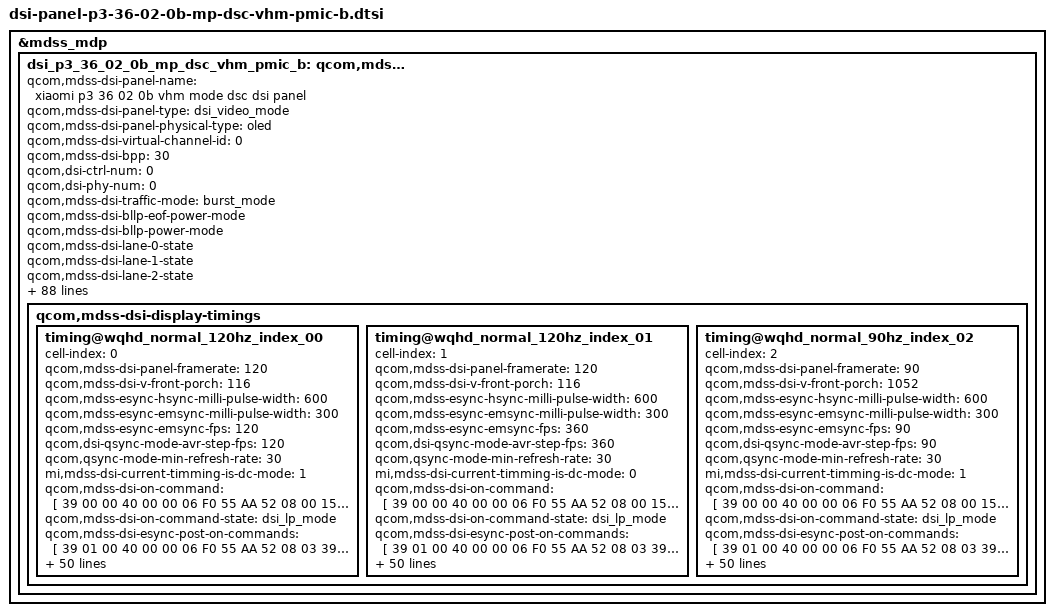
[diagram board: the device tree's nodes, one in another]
&mdss_mdp {
	dsi_p3_36_02_0b_mp_dsc_vhm_pmic_b: qcom,mdss_dsi_p3_36_02_0b_mp_dsc_vhm_pmic_b {
		qcom,mdss-dsi-panel-name = "xiaomi p3 36 02 0b vhm mode dsc dsi panel";
		qcom,mdss-dsi-panel-type = "dsi_video_mode";
		qcom,mdss-dsi-panel-physical-type = "oled";
		qcom,mdss-dsi-virtual-channel-id = <0>;
		qcom,mdss-dsi-bpp = <30>;
		qcom,dsi-ctrl-num = <0>;
		qcom,dsi-phy-num = <0>;
		qcom,mdss-dsi-traffic-mode = "burst_mode";
		qcom,mdss-dsi-bllp-eof-power-mode;
		qcom,mdss-dsi-bllp-power-mode;
		qcom,mdss-dsi-lane-0-state;
		qcom,mdss-dsi-lane-1-state;
		qcom,mdss-dsi-lane-2-state;
		qcom,mdss-dsi-lane-3-state;
		qcom,mdss-dsi-color-order = "rgb_swap_rgb";
		qcom,mdss-dsi-dma-trigger = "trigger_sw";
		qcom,mdss-dsi-mdp-trigger = "none";
		qcom,mdss-dsi-reset-sequence =<1 1>, <0 3>, <1 15>;
		qcom,mdss-pan-physical-width-dimension = <673>;
		qcom,mdss-pan-physical-height-dimension = <1466>;
		qcom,mdss-dsi-te-pin-select = <1>;
		qcom,mdss-dsi-wr-mem-start = <0x2c>;
		qcom,mdss-dsi-wr-mem-continue = <0x3c>;
		qcom,mdss-dsi-tx-eot-append;
		qcom,mdss-dsi-lp11-init;
		qcom,mdss-dsi-bl-inverted-dbv;
		qcom,bl-update-flag = "delay_until_first_frame";
		qcom,mdss-dsi-panel-hdr-enabled;
		qcom,mdss-dsi-panel-hdr-color-primaries = <14500 15500 32000
			17000 15500 30000 8000 3000>;
		qcom,mdss-dsi-panel-peak-brightness = <32000000>;
		qcom,mdss-dsi-panel-blackness-level = <3230>;
		//qcom,mdss-dsi-dma-schedule-line = <1>;
		//qcom,mdss-dsi-dma-schedule-window = <50>;
		qcom,spr-pack-type = "pentile";
		/*
		 * ###############################################################
		 * # Pentile SPR phases for SM8850 and later
		 * ###############################################################
		 * # RG/BG Type A    BG/RG Type A    GR/GB Type A    GB/GR Type A
		 * # R B R B ...     B R B R ...      R B R B ...     B R B R ...
		 * #  G G G G ...     G G G G ...    G G G G ...     G G G G ...
		 * #
		 * # RG/BG Type B    BG/RG Type B    GR/GB Type B    GB/GR Type B
		 * #  G G G G ...     G G G G ...    G G G G ...     G G G G ...
		 * # R B R B ...     B R B R ...      R B R B ...     B R B R ...
		 * ###############################################################
		 */
		qcom,spr-pentile-pack-type = "BG-RG Type A";
		xiaomi,mdss-panel-need-post-on-supply;
		xiaomi,mdss-dsi-gesture-reset-sequence = <0 10>, <1 5>, <0 3>, <1 15>;

		qcom,mdss-disable-cesta-hw-sleep;

		qcom,mdss-dsi-display-timings {
			timing@wqhd_normal_120hz_index_00 {
				#include "dsi-panel-p3-36-02-0b-mp-dsc-vhm-pmic-b-common.dtsi"
				cell-index = <0>;
				qcom,mdss-dsi-panel-framerate = <120>;

				qcom,mdss-dsi-v-front-porch = <116>;
				qcom,mdss-esync-hsync-milli-pulse-width = <600>;
				qcom,mdss-esync-emsync-milli-pulse-width = <300>;
				qcom,mdss-esync-emsync-fps = <120>;
				qcom,dsi-qsync-mode-avr-step-fps = <120>;
				qcom,qsync-mode-min-refresh-rate = <30>;

				mi,mdss-dsi-current-timming-is-dc-mode = <1>;

				qcom,mdss-dsi-on-command = [
					// dbv_vld_dly_em=2
					39 00 00 40 00 00 06 F0 55 AA 52 08 00
					15 00 00 40 00 00 02 6F 70
					15 00 00 00 00 00 02 B2 02
					// EN_SSD=0
					15 00 00 40 00 00 02 6F 53
					15 00 00 00 00 00 02 D5 17
					// AP_SPR_in_Setting(RGBG)
					39 00 00 40 00 00 06 F0 55 AA 52 08 03
					15 00 00 40 00 00 02 6F 09
					39 00 00 00 00 00 07 DE 30 14 25 10 34 25
					// EM_STV_DSPOFF_MASK_OPT=1
					15 00 00 40 00 00 02 6F 10
					15 00 00 00 00 00 02 B6 15
					// External DVDD opt
					39 00 00 40 00 00 06 F0 55 AA 52 08 01
					15 00 00 40 00 00 02 6F 81
					15 00 00 00 00 00 02 C2 C2
					// AVEE_AB_HIZ
					15 00 00 40 00 00 02 6F 02
					15 00 00 00 00 00 02 C7 45
					// AP SPR IN VESA Setting
					39 00 00 40 00 00 05 2A 00 00 04 C3
					39 00 00 40 00 00 05 2B 00 00 0A 5F
					39 00 00 40 00 00 03 90 03 43
					39 00 00 40 00 00 13 91 AB F0 00 10 C1 00 01 CB 00 73 00 33 06 67 1F B0 11 40
					39 00 00 40 00 00 06 F0 55 AA 52 08 07
					39 00 00 40 00 00 06 B0 84 44 00 00 40
					15 00 00 00 00 00 02 26 00
					// TE on
					39 00 00 40 00 00 04 2F 30 05 30
					15 00 00 40 00 00 02 35 00
					15 00 00 40 00 00 02 6F 04
					15 00 00 40 00 00 02 35 00
					// TEx_sel
					15 00 00 00 00 00 02 6F 14
					39 00 00 40 00 00 04 35 6A 77 F8
					15 00 00 40 00 00 02 6F 17
					39 00 00 40 00 00 04 35 6A 77 F8
					15 00 00 40 00 00 02 6F 1A
					39 00 00 40 00 00 04 35 6A 77 F8
					15 00 00 40 00 00 02 6F 1D
					39 00 00 40 00 00 04 35 6A 77 F8
					15 00 00 40 00 00 02 6F 02
					15 00 00 40 00 00 02 35 18
					15 00 00 40 00 00 02 6F 0C
					15 00 00 40 00 00 02 35 00
					39 00 00 00 00 00 03 44 0A 60
					// dyn_multi_te_start
					15 00 00 40 00 00 02 6F 26
					39 00 00 40 00 00 03 44 00 78
					15 00 00 40 00 00 02 6F 28
					39 00 00 40 00 00 03 44 00 78
					15 00 00 40 00 00 02 6F 42
					39 00 00 40 00 00 03 44 00 78
					15 00 00 40 00 00 02 6F 64
					39 00 00 00 00 00 03 44 00 78
					// opt_level2_te_fall
					15 00 00 40 00 00 02 6F 8A
					15 00 00 00 00 00 02 44 19
					// dyn_multi_te_width
					15 00 00 40 00 00 02 6F 2A
					15 00 00 40 00 00 02 44 1A
					// still=0
					15 00 00 40 00 00 02 18 00
					// Event_Mode
					15 00 00 40 00 00 02 8C 02
					// opt_dsp_on_restart_fskip
					39 00 00 40 00 00 04 8D 00 20 00
					// opt_dis_vdo_ltpo_crc
					39 00 00 40 00 00 06 F0 55 AA 52 08 00
					15 00 00 40 00 00 02 6F DD
					15 00 00 00 00 00 02 BA 80
					// ARP_TE selects TE1F
					15 00 00 40 00 00 02 6F 35
					15 00 00 00 00 00 02 B1 10
					// SEL_ECK_CYCLE_LINE=0
					15 00 00 40 00 00 02 6F 04
					// EXTEND_VFP_LINE_ECLK_EN=0
					15 00 00 40 00 00 02 BA 00
					// tg_cmd2_opt18
					15 00 00 40 00 00 02 6F E2
					15 00 00 00 00 00 02 BA 08
					// TG_OPT2
					39 00 00 40 00 00 05 FF AA 55 A5 81
					15 00 00 40 00 00 02 6F 00
					15 00 00 40 00 00 02 FB 10
					39 00 00 40 00 00 04 8C 02 00 10
					15 00 00 40 00 00 02 6F 06
					15 00 00 40 00 00 02 6D 08
					15 00 00 00 00 00 02 53 20
					// Nor_51 00
					39 00 00 40 00 00 03 51 00 00
					// AOD_51 00
					15 00 00 40 00 00 02 6F 04
					39 00 00 00 00 00 03 51 00 00
					// 120 Hz
					15 00 00 40 00 00 02 6D 00
					// Video drop opt
					39 00 00 40 00 00 05 FF AA 55 A5 84
					15 00 00 40 00 00 02 6F 21
					15 00 00 00 00 00 02 F8 7A
					// EXT HSYNC EN
					39 00 00 40 00 00 06 F0 55 AA 52 08 03
					15 00 00 40 00 00 02 6F 06
					15 00 00 40 00 00 02 BA 00
					15 00 00 40 00 00 02 C6 87
					15 00 00 40 00 00 02 6F 2A
					15 00 00 40 00 00 02 C6 40
					39 00 00 00 00 00 06 F0 55 AA 52 08 05
					// EN AUTO VBPREM
					15 00 00 40 00 00 02 B0 9F
					// VBP EXT Setting
					39 00 00 40 00 00 05 3B 00 24 00 74
					15 00 00 40 00 00 02 6F 04
					39 00 00 40 00 00 05 3B 00 24 04 1C
					15 00 00 40 00 00 02 6F 08
					39 00 00 40 00 00 05 3B 00 24 00 74
					15 00 00 40 00 00 02 6F 10
					39 00 00 00 00 00 05 3B 00 24 00 74
					// Set DSI Mode
					15 00 00 40 00 00 02 71 01
					// Esd detection
					39 00 00 40 00 00 06 F0 55 AA 52 08 00
					15 00 00 40 00 00 02 6F 01
					15 00 00 00 00 00 02 BE 45
					// LVD on
					39 00 00 40 00 00 06 F0 55 AA 52 08 01
					15 00 00 40 00 00 02 6F 03
					15 00 00 00 00 00 02 C7 47
					// Small Pulse
					39 00 00 40 00 00 06 F0 55 AA 52 08 03
					15 00 00 40 00 00 02 6F 2A
					39 00 00 40 00 00 03 C6 40 20
					15 00 00 40 00 00 02 6F 33
					39 00 00 00 00 00 0D C6 00 20 00 20 00 20 00 20 00 20 00 20
					// Esd off
					39 00 00 40 00 00 06 F0 55 AA 52 08 00
					15 00 00 40 00 00 02 6F 05
					15 00 00 00 00 00 02 BE 00
					// VHM setting,DC first writes 6D, then writes common
					// 5.2.2.12 6D=0B
					15 01 00 40 00 00 02 6F 2D
					39 01 00 40 00 00 08 44 00 1A 00 1A 1A 0A F8
					15 01 00 40 00 00 02 6F 3B
					39 01 00 40 00 00 08 44 00 1A 00 1A 1A 0A F8
					15 01 00 40 00 00 02 6F 2B
					39 01 00 40 00 00 03 44 0A F8
					15 01 00 40 00 00 02 6F 6B
					15 01 00 40 00 00 02 44 01
					39 01 00 40 00 00 03 44 0A 60
					39 01 00 40 00 00 06 F0 55 AA 52 08 00
					15 01 00 40 00 00 02 6F 0E
					15 01 00 40 00 00 02 C0 00
					15 01 00 40 00 00 02 6F DE
					15 01 00 40 00 00 02 BA 00
					15 01 00 40 00 00 02 6F 04
					15 01 00 40 00 00 02 35 01
					15 01 00 40 00 00 02 6F 14
					15 01 00 40 00 00 02 35 6A
					15 01 00 40 00 00 02 6D 0B
					// DC switch add
					// FFD_DC
					39 00 00 40 00 00 06 F0 55 AA 52 08 08
					39 00 00 40 00 00 0F E1 0E 1C 16 16 16 16 19 19 30 22 1B 17 1A 5C
					15 00 00 40 00 00 02 6F 0E
					39 00 00 40 00 00 0F E1 08 0F 10 14 14 14 14 14 14 26 28 2A 2C 2D
					15 00 00 40 00 00 02 6F 1C
					39 00 00 40 00 00 0F E1 04 08 08 08 08 08 08 09 09 0E 16 1C 1C 25
					15 00 00 40 00 00 02 6F 2A
					39 00 00 40 00 00 0F E1 04 08 08 08 08 09 09 09 09 12 16 1A 1C 25
					15 00 00 40 00 00 02 6F 38
					39 00 00 40 00 00 0F E1 01 03 04 04 04 04 04 08 0F 15 17 1D 1C 26
					39 00 00 40 00 00 0F E2 0B 16 18 18 18 18 1A 1A 1A 27 1A 18 1D 37
					15 00 00 40 00 00 02 6F 0E
					39 00 00 40 00 00 0F E2 09 12 16 16 16 16 16 16 1A 20 23 26 29 2B
					15 00 00 40 00 00 02 6F 1C
					39 00 00 40 00 00 0F E2 00 01 0A 0C 0C 0C 0C 12 0E 0D 11 12 20 29
					15 00 00 40 00 00 02 6F 2A
					39 00 00 40 00 00 0F E2 03 07 0A 0C 0C 0C 0C 0C 09 0E 12 16 21 2B
					15 00 00 40 00 00 02 6F 38
					39 00 00 40 00 00 0F E2 02 04 05 05 05 05 05 08 09 0E 12 18 21 2C
					39 00 00 40 00 00 0F E3 00 00 01 01 01 01 00 00 00 00 00 00 00 00
					15 00 00 40 00 00 02 6F 0E
					39 00 00 40 00 00 0F E3 00 01 01 01 01 01 01 01 01 02 02 10 00 00
					15 00 00 40 00 00 02 6F 1C
					39 00 00 40 00 00 0F E3 00 01 01 01 01 01 01 08 00 00 00 00 00 00
					15 00 00 40 00 00 02 6F 2A
					39 00 00 40 00 00 0F E3 00 00 00 05 05 05 05 05 05 04 00 00 00 00
					15 00 00 40 00 00 02 6F 38
					39 00 00 40 00 00 0F E3 00 00 01 01 02 07 08 08 07 0C 12 16 1A 22
					// LFCC_DC_LUT
					15 00 00 40 00 00 02 68 00
					// LFCC_COM
					39 00 00 40 00 00 1A A9 10 2F 00 02 30 05 30 29 BD 00 00 05 10 A2 00 08 05 00 00 01 29 BD 00 00 04
					// DC switch
					39 01 00 40 00 00 06 F0 55 AA 52 08 00
					15 01 00 40 00 00 02 6F B8
					39 01 00 40 00 00 09 BA 10 10 00 00 00 01 20 21
					15 01 00 40 00 00 02 6F C0
					39 01 00 40 00 00 09 BA 10 10 00 00 00 01 20 21
					15 01 00 40 00 00 02 6F 5A
					39 01 00 40 00 00 09 D1 10 10 00 00 00 01 20 21
					15 01 00 40 00 00 02 6F 31
					15 01 00 40 00 00 02 C0 00
					39 01 00 40 00 00 03 5A 00 00
					// DC VrefN1/N3 tracking ELVSS
					39 01 00 40 00 00 06 F0 55 AA 52 08 01
					15 01 00 40 00 00 02 6F 19
					39 01 00 40 00 00 06 BA 03 03 03 03 03
					15 01 00 40 00 00 02 6F 3B
					39 01 00 40 00 00 06 BA 0C 0C 0C 0C 0C
					// video trim
					39 01 00 40 00 00 06 F0 55 AA 52 08 01
					39 01 00 40 00 00 37 C3 DD 11 02 5D E3 00 11 00 5D E3 00 3F 40 FD 3F 34 DB 3F 40 FD 3F 34 DB 3F 40 FD 3F 34 DB 3F 40 FD 3F 34 DB 3F 4A E1 3F 30 A0 00 00 01 00 00 01 22 C0 AA 02 AA 02 00
					39 01 00 00 00 00 24 EA D1 02 3C 00 04 08 80 01 72 01 72 D1 02 3C 00 07 08 80 01 AC 01 AC 00 00 00 00 01 72 01 AC 00 0C 00 00 40
					// Sleep Out
					05 00 00 00 78 00 01 11
					// Display On
					05 00 00 00 00 00 01 29
					// Esd on
					39 00 00 40 00 00 06 F0 55 AA 52 08 00
					15 00 00 40 00 00 02 6F 05
					15 00 00 00 00 00 02 BE 08
				];
				qcom,mdss-dsi-on-command-state = "dsi_lp_mode";

				qcom,mdss-dsi-esync-post-on-commands = [
					39 01 00 40 00 00 06 F0 55 AA 52 08 03
					39 01 00 40 00 00 02 6F 06
					// 00 -> MIPI Hsync  01 -> Ext Hsync
					39 01 00 00 00 00 02 BA 01
				];
				qcom,mdss-dsi-esync-post-on-commands-state = "dsi_hs_mode";

				qcom,mdss-dsi-qsync-freq-step-sequence-interval =
					<0 120000 1>, <0 60000 1>, <1 120000 1>, <1 60000 1>;
				qcom,mdss-dsi-qsync-freq-step-sequence  =
					<30000 1>,
					<30000 1>,
					<30000 1>,
					<30000 1>;

				qcom,mdss-dsi-qsync-freq-pattren-needs-selfrefresh =
					<1 1 1 1>;

				qcom,mdss-dsi-freq-step-pattern1-command = [
					// Non Cmd Setting
					15 01 00 00 00 00 02 6F 00
				];
				qcom,mdss-dsi-freq-step-pattern1-command-state = "dsi_lp_mode";

				qcom,mdss-dsi-freq-step-pattern2-command = [
					// Non Cmd Setting
					15 01 00 00 00 00 02 6F 00
				];
				qcom,mdss-dsi-freq-step-pattern2-command-state = "dsi_lp_mode";

				qcom,mdss-dsi-freq-step-pattern3-command = [
					// Non Cmd Setting
					15 01 00 00 00 00 02 6F 00
				];
				qcom,mdss-dsi-freq-step-pattern3-command-state = "dsi_lp_mode";

				qcom,mdss-dsi-freq-step-pattern4-command = [
					// Non Cmd Setting
					15 01 00 00 00 00 02 6F 00
				];
				qcom,mdss-dsi-freq-step-pattern4-command-state = "dsi_lp_mode";

				qcom,mdss-dsi-sticky_still_en-command = [
					39 01 00 00 00 00 11 A9 10 18 00 00 01 20 D1 6E 6F 3F F0 20 BE 02 02 60
				];
				qcom,mdss-dsi-sticky_still_en-command-state = "dsi_hs_mode";

				qcom,mdss-dsi-sticky_still_disable-command = [
					39 01 00 00 00 00 11 A9 10 18 00 00 00 20 D1 6E 6F FF FF 20 BE 02 02 47
				];
				qcom,mdss-dsi-sticky_still_disable-command-state = "dsi_hs_mode";

				qcom,mdss-dsi-em-pulse-switch-command = [
					// VHM setting,DC first writes 6D, then writes common
					// DC 120HZ
					// 5.2.2.12
					15 01 00 40 00 00 02 6F 2D
					39 01 00 40 00 00 08 44 00 1A 00 1A 1A 0A F8
					15 01 00 40 00 00 02 6F 3B
					39 01 00 40 00 00 08 44 00 1A 00 1A 1A 0A F8
					15 01 00 40 00 00 02 6F 2B
					39 01 00 40 00 00 03 44 0A F8
					15 01 00 40 00 00 02 6F 6B
					15 01 00 40 00 00 02 44 01
					39 01 00 40 00 00 03 44 0A 60
					39 01 00 40 00 00 06 F0 55 AA 52 08 00
					15 01 00 40 00 00 02 6F 0E
					15 01 00 40 00 00 02 C0 00
					15 01 00 40 00 00 02 6F DE
					15 01 00 40 00 00 02 BA 00
					15 01 00 40 00 00 02 6F 04
					15 01 00 40 00 00 02 35 01
					15 01 00 40 00 00 02 6F 14
					15 01 00 40 00 00 02 35 6A
					15 01 00 00 00 00 02 6D 0B
				];
				qcom,mdss-dsi-em-pulse-switch-command-state = "dsi_hs_mode";

				mi,mdss-dsi-em-pulse-supplement-switch-command = [
					// VHM setting,DC first writes 6D, then writes common
					// 5.2.2.12 6D=0B
					15 01 00 40 00 00 02 6F 2D
					39 01 00 40 00 00 08 44 00 1A 00 1A 1A 0A F8
					15 01 00 40 00 00 02 6F 3B
					39 01 00 40 00 00 08 44 00 1A 00 1A 1A 0A F8
					15 01 00 40 00 00 02 6F 2B
					39 01 00 40 00 00 03 44 0A F8
					15 01 00 40 00 00 02 6F 6B
					15 01 00 40 00 00 02 44 01
					39 01 00 40 00 00 03 44 0A 60
					39 01 00 40 00 00 06 F0 55 AA 52 08 00
					15 01 00 40 00 00 02 6F 0E
					15 01 00 40 00 00 02 C0 00
					15 01 00 40 00 00 02 6F DE
					15 01 00 40 00 00 02 BA 00
					15 01 00 40 00 00 02 6F 04
					15 01 00 40 00 00 02 35 01
					15 01 00 40 00 00 02 6F 14
					15 01 00 40 00 00 02 35 6A
					15 01 00 40 00 00 02 6D 0B
					// DC switch add
					// FFD_DC
					39 00 00 40 00 00 06 F0 55 AA 52 08 08
					39 00 00 40 00 00 0F E1 0E 1C 16 16 16 16 19 19 30 22 1B 17 1A 5C
					15 00 00 40 00 00 02 6F 0E
					39 00 00 40 00 00 0F E1 08 0F 10 14 14 14 14 14 14 26 28 2A 2C 2D
					15 00 00 40 00 00 02 6F 1C
					39 00 00 40 00 00 0F E1 04 08 08 08 08 08 08 09 09 0E 16 1C 1C 25
					15 00 00 40 00 00 02 6F 2A
					39 00 00 40 00 00 0F E1 04 08 08 08 08 09 09 09 09 12 16 1A 1C 25
					15 00 00 40 00 00 02 6F 38
					39 00 00 40 00 00 0F E1 01 03 04 04 04 04 04 08 0F 15 17 1D 1C 26
					39 00 00 40 00 00 0F E2 0B 16 18 18 18 18 1A 1A 1A 27 1A 18 1D 37
					15 00 00 40 00 00 02 6F 0E
					39 00 00 40 00 00 0F E2 09 12 16 16 16 16 16 16 1A 20 23 26 29 2B
					15 00 00 40 00 00 02 6F 1C
					39 00 00 40 00 00 0F E2 00 01 0A 0C 0C 0C 0C 12 0E 0D 11 12 20 29
					15 00 00 40 00 00 02 6F 2A
					39 00 00 40 00 00 0F E2 03 07 0A 0C 0C 0C 0C 0C 09 0E 12 16 21 2B
					15 00 00 40 00 00 02 6F 38
					39 00 00 40 00 00 0F E2 02 04 05 05 05 05 05 08 09 0E 12 18 21 2C
					39 00 00 40 00 00 0F E3 00 00 01 01 01 01 00 00 00 00 00 00 00 00
					15 00 00 40 00 00 02 6F 0E
					39 00 00 40 00 00 0F E3 00 01 01 01 01 01 01 01 01 02 02 10 00 00
					15 00 00 40 00 00 02 6F 1C
					39 00 00 40 00 00 0F E3 00 01 01 01 01 01 01 08 00 00 00 00 00 00
					15 00 00 40 00 00 02 6F 2A
					39 00 00 40 00 00 0F E3 00 00 00 05 05 05 05 05 05 04 00 00 00 00
					15 00 00 40 00 00 02 6F 38
					39 00 00 40 00 00 0F E3 00 00 01 01 02 07 08 08 07 0C 12 16 1A 22
					// LFCC_DC_LUT
					15 00 00 40 00 00 02 68 00
					// LFCC_COM
					39 00 00 40 00 00 1A A9 10 2F 00 02 30 05 30 29 BD 00 00 05 10 A2 00 08 05 00 00 01 29 BD 00 00 04
					// DC switch
					39 01 00 40 00 00 06 F0 55 AA 52 08 00
					15 01 00 40 00 00 02 6F B8
					39 01 00 40 00 00 09 BA 10 10 00 00 00 01 20 21
					15 01 00 40 00 00 02 6F C0
					39 01 00 40 00 00 09 BA 10 10 00 00 00 01 20 21
					15 01 00 40 00 00 02 6F 5A
					39 01 00 40 00 00 09 D1 10 10 00 00 00 01 20 21
					15 01 00 40 00 00 02 6F 31
					15 01 00 40 00 00 02 C0 00
					39 01 00 40 00 00 03 5A 00 00
					// DC VrefN1/N3 tracking ELVSS
					39 01 00 40 00 00 06 F0 55 AA 52 08 01
					15 01 00 40 00 00 02 6F 19
					39 01 00 40 00 00 06 BA 03 03 03 03 03
					15 01 00 40 00 00 02 6F 3B
					39 01 00 40 00 00 06 BA 0C 0C 0C 0C 0C
					// Temp value
					39 01 00 00 00 00 03 81 03 1B
				];
				mi,mdss-dsi-em-pulse-supplement-switch-command-state = "dsi_hs_mode";
				mi,mdss-dsi-em-pulse-supplement-switch-command-update = <0x81 64 2>;

				mi,mdss-dsi-demura-over-threshold-command = [
					15 01 00 00 00 00 02 6F 00
				];
				mi,mdss-dsi-demura-over-threshold-command-state = "dsi_hs_mode";

				mi,mdss-dsi-demura-under-threshold-command = [
					15 01 00 00 00 00 02 6F 00
				];
				mi,mdss-dsi-demura-under-threshold-command-state = "dsi_hs_mode";
			};

			timing@wqhd_normal_120hz_index_01 {
				#include "dsi-panel-p3-36-02-0b-mp-dsc-vhm-pmic-b-common.dtsi"
				cell-index = <1>;
				qcom,mdss-dsi-panel-framerate = <120>;

				qcom,mdss-dsi-v-front-porch = <116>;
				qcom,mdss-esync-hsync-milli-pulse-width = <600>;
				qcom,mdss-esync-emsync-milli-pulse-width = <300>;
				qcom,mdss-esync-emsync-fps = <360>;
				qcom,dsi-qsync-mode-avr-step-fps = <360>;
				qcom,qsync-mode-min-refresh-rate = <30>;

				mi,mdss-dsi-current-timming-is-dc-mode = <0>;

				qcom,mdss-dsi-on-command = [
					// dbv_vld_dly_em=2
					39 00 00 40 00 00 06 F0 55 AA 52 08 00
					15 00 00 40 00 00 02 6F 70
					15 00 00 00 00 00 02 B2 02
					// EN_SSD=0
					15 00 00 40 00 00 02 6F 53
					15 00 00 00 00 00 02 D5 17
					// AP_SPR_in_Setting(RGBG)
					39 00 00 40 00 00 06 F0 55 AA 52 08 03
					15 00 00 40 00 00 02 6F 09
					39 00 00 00 00 00 07 DE 30 14 25 10 34 25
					// EM_STV_DSPOFF_MASK_OPT=1
					15 00 00 40 00 00 02 6F 10
					15 00 00 00 00 00 02 B6 15
					// External DVDD opt
					39 00 00 40 00 00 06 F0 55 AA 52 08 01
					15 00 00 40 00 00 02 6F 81
					15 00 00 00 00 00 02 C2 C2
					// AVEE_AB_HIZ
					15 00 00 40 00 00 02 6F 02
					15 00 00 00 00 00 02 C7 45
					// AP SPR IN VESA Setting
					39 00 00 40 00 00 05 2A 00 00 04 C3
					39 00 00 40 00 00 05 2B 00 00 0A 5F
					39 00 00 40 00 00 03 90 03 43
					39 00 00 40 00 00 13 91 AB F0 00 10 C1 00 01 CB 00 73 00 33 06 67 1F B0 11 40
					39 00 00 40 00 00 06 F0 55 AA 52 08 07
					39 00 00 40 00 00 06 B0 84 44 00 00 40
					15 00 00 00 00 00 02 26 00
					// TE on
					39 00 00 40 00 00 04 2F 30 05 30
					15 00 00 40 00 00 02 35 00
					15 00 00 40 00 00 02 6F 04
					15 00 00 40 00 00 02 35 00
					// TEx_sel
					15 00 00 00 00 00 02 6F 14
					39 00 00 40 00 00 04 35 6A 77 F8
					15 00 00 40 00 00 02 6F 17
					39 00 00 40 00 00 04 35 6A 77 F8
					15 00 00 40 00 00 02 6F 1A
					39 00 00 40 00 00 04 35 6A 77 F8
					15 00 00 40 00 00 02 6F 1D
					39 00 00 40 00 00 04 35 6A 77 F8
					15 00 00 40 00 00 02 6F 02
					15 00 00 40 00 00 02 35 18
					15 00 00 40 00 00 02 6F 0C
					15 00 00 40 00 00 02 35 00
					39 00 00 00 00 00 03 44 0A 60
					// dyn_multi_te_start
					15 00 00 40 00 00 02 6F 26
					39 00 00 40 00 00 03 44 00 78
					15 00 00 40 00 00 02 6F 28
					39 00 00 40 00 00 03 44 00 78
					15 00 00 40 00 00 02 6F 42
					39 00 00 40 00 00 03 44 00 78
					15 00 00 40 00 00 02 6F 64
					39 00 00 00 00 00 03 44 00 78
					// opt_level2_te_fall
					15 00 00 40 00 00 02 6F 8A
					15 00 00 00 00 00 02 44 19
					// dyn_multi_te_width
					15 00 00 40 00 00 02 6F 2A
					15 00 00 40 00 00 02 44 1A
					// still=0
					15 00 00 40 00 00 02 18 00
					// Event_Mode
					15 00 00 40 00 00 02 8C 02
					// opt_dsp_on_restart_fskip
					39 00 00 40 00 00 04 8D 00 20 00
					// opt_dis_vdo_ltpo_crc
					39 00 00 40 00 00 06 F0 55 AA 52 08 00
					15 00 00 40 00 00 02 6F DD
					15 00 00 00 00 00 02 BA 80
					// ARP_TE selects TE1F
					15 00 00 40 00 00 02 6F 35
					15 00 00 00 00 00 02 B1 10
					// SEL_ECK_CYCLE_LINE=0
					15 00 00 40 00 00 02 6F 04
					// EXTEND_VFP_LINE_ECLK_EN=0
					15 00 00 40 00 00 02 BA 00
					// tg_cmd2_opt18
					15 00 00 40 00 00 02 6F E2
					15 00 00 00 00 00 02 BA 08
					// TG_OPT2
					39 00 00 40 00 00 05 FF AA 55 A5 81
					15 00 00 40 00 00 02 6F 00
					15 00 00 40 00 00 02 FB 10
					39 00 00 40 00 00 04 8C 02 00 10
					15 00 00 40 00 00 02 6F 06
					15 00 00 40 00 00 02 6D 08
					15 00 00 00 00 00 02 53 20
					// Nor_51 00
					39 00 00 40 00 00 03 51 00 00
					// AOD_51 00
					15 00 00 40 00 00 02 6F 04
					39 00 00 00 00 00 03 51 00 00
					// 120 Hz
					15 00 00 40 00 00 02 6D 00
					// Video drop opt
					39 00 00 40 00 00 05 FF AA 55 A5 84
					15 00 00 40 00 00 02 6F 21
					15 00 00 00 00 00 02 F8 7A
					// EXT HSYNC EN
					39 00 00 40 00 00 06 F0 55 AA 52 08 03
					15 00 00 40 00 00 02 6F 06
					15 00 00 40 00 00 02 BA 00
					15 00 00 40 00 00 02 C6 87
					15 00 00 40 00 00 02 6F 2A
					15 00 00 40 00 00 02 C6 40
					39 00 00 00 00 00 06 F0 55 AA 52 08 05
					// EN AUTO VBPREM
					15 00 00 40 00 00 02 B0 9F
					// VBP EXT Setting
					39 00 00 40 00 00 05 3B 00 24 00 74
					15 00 00 40 00 00 02 6F 04
					39 00 00 40 00 00 05 3B 00 24 04 1C
					15 00 00 40 00 00 02 6F 08
					39 00 00 40 00 00 05 3B 00 24 00 74
					15 00 00 40 00 00 02 6F 10
					39 00 00 00 00 00 05 3B 00 24 00 74
					// Set DSI Mode
					15 00 00 40 00 00 02 71 01
					// Esd detection
					39 00 00 40 00 00 06 F0 55 AA 52 08 00
					15 00 00 40 00 00 02 6F 01
					15 00 00 00 00 00 02 BE 45
					// LVD on
					39 00 00 40 00 00 06 F0 55 AA 52 08 01
					15 00 00 40 00 00 02 6F 03
					15 00 00 00 00 00 02 C7 47
					// Small Pulse
					39 00 00 40 00 00 06 F0 55 AA 52 08 03
					15 00 00 40 00 00 02 6F 2A
					39 00 00 40 00 00 03 C6 40 20
					15 00 00 40 00 00 02 6F 33
					39 00 00 00 00 00 0D C6 00 20 00 20 00 20 00 20 00 20 00 20
					// Esd off
					39 00 00 40 00 00 06 F0 55 AA 52 08 00
					15 00 00 40 00 00 02 6F 05
					15 00 00 00 00 00 02 BE 00
					// VHM setting, PWM write common first, then write 6D
					// pwm SWITCH add
					// FFD_PWM
					39 00 00 40 00 00 06 F0 55 AA 52 08 08
					39 00 00 40 00 00 0F E1 0E 1C 2B 39 39 39 39 39 39 22 1B 17 1A 5C
					15 00 00 40 00 00 02 6F 0E
					39 00 00 40 00 00 0F E1 08 0F 16 1F 1F 1F 1F 1F 19 26 28 2A 2C 2D
					15 00 00 40 00 00 02 6F 1C
					39 00 00 40 00 00 0F E1 04 08 0B 0B 0B 0B 0B 0B 0B 0E 16 1C 1C 25
					15 00 00 40 00 00 02 6F 2A
					39 00 00 40 00 00 0F E1 04 08 0D 0B 0B 0E 0E 0D 0B 12 16 1A 1C 25
					15 00 00 40 00 00 02 6F 38
					39 00 00 40 00 00 0F E1 01 03 05 0B 06 07 08 08 0F 15 17 1D 1C 26
					39 00 00 40 00 00 0F E2 0B 16 21 2C 2C 2C 2C 2C 2C 27 1E 18 1D 37
					15 00 00 40 00 00 02 6F 0E
					39 00 00 40 00 00 0F E2 09 12 1B 24 24 24 24 24 1A 20 23 26 29 2B
					15 00 00 40 00 00 02 6F 1C
					39 00 00 40 00 00 0F E2 00 01 03 08 0A 0B 0F 12 0E 0D 11 12 20 29
					15 00 00 40 00 00 02 6F 2A
					39 00 00 40 00 00 0F E2 03 07 0A 0C 0C 0C 0C 0B 09 0E 12 16 21 2B
					15 00 00 40 00 00 02 6F 38
					39 00 00 40 00 00 0F E2 02 05 08 08 08 08 09 08 09 0E 12 18 21 2C
					39 00 00 40 00 00 0F E3 00 00 00 00 00 00 00 00 00 00 00 00 00 00
					15 00 00 40 00 00 02 6F 0E
					39 00 00 40 00 00 0F E3 00 00 00 00 00 00 00 00 00 00 00 00 00 00
					15 00 00 40 00 00 02 6F 1C
					39 00 00 40 00 00 0F E3 00 00 00 00 00 00 00 08 00 00 00 00 00 00
					15 00 00 40 00 00 02 6F 2A
					39 00 00 40 00 00 0F E3 00 00 00 00 05 05 05 05 05 04 00 00 00 00
					15 00 00 40 00 00 02 6F 38
					39 00 00 40 00 00 0F E3 00 00 00 01 02 06 08 08 07 0C 12 16 1A 22
					// LFCC_PWM_LUT
					15 00 00 40 00 00 02 68 10
					// LFCC_COM
					39 00 00 40 00 00 1A A9 10 2F 00 02 30 05 30 29 BD 00 00 05 10 A2 00 08 05 00 00 01 29 BD 00 00 04
					// pwm SWITCH
					39 01 00 40 00 00 06 F0 55 AA 52 08 00
					15 01 00 40 00 00 02 6F B8
					39 01 00 40 00 00 09 BA 22 22 22 22 22 22 22 21
					15 01 00 40 00 00 02 6F C0
					39 01 00 40 00 00 09 BA 22 22 22 22 22 22 22 21
					15 01 00 40 00 00 02 6F 5A
					39 01 00 40 00 00 09 D1 22 22 22 22 22 22 22 21
					15 01 00 40 00 00 02 6F 31
					15 01 00 40 00 00 02 C0 02
					39 01 00 40 00 00 03 5A 00 00
					// PWM VrefN1/N3 tracking ELVSS
					39 01 00 40 00 00 06 F0 55 AA 52 08 01
					15 01 00 40 00 00 02 6F 19
					39 01 00 40 00 00 06 BA 02 02 02 02 02
					15 01 00 40 00 00 02 6F 3B
					39 01 00 40 00 00 06 BA 0B 0B 0B 0B 0B
					// 6d=87
					15 01 00 40 00 00 02 6F 2D
					39 01 00 40 00 00 08 44 00 1A 00 1A 1A 0A F8
					15 01 00 40 00 00 02 6F 3B
					39 01 00 40 00 00 08 44 00 1A 00 1A 1A 0A F8
					15 01 00 40 00 00 02 6F 2B
					39 01 00 40 00 00 03 44 03 A8
					15 01 00 40 00 00 02 6F 6B
					15 01 00 40 00 00 02 44 01
					39 01 00 40 00 00 03 44 0A 60
					39 01 00 40 00 00 06 F0 55 AA 52 08 00
					15 01 00 40 00 00 02 6F 0E
					15 01 00 40 00 00 02 C0 00
					15 01 00 40 00 00 02 6F DE
					15 01 00 40 00 00 02 BA 00
					15 01 00 40 00 00 02 6F 04
					15 01 00 40 00 00 02 35 00
					15 01 00 40 00 00 02 6F 14
					15 01 00 40 00 00 02 35 6A
					15 01 00 40 00 00 02 6D 87
					// video trim
					39 01 00 40 00 00 06 F0 55 AA 52 08 01
					39 01 00 40 00 00 37 C3 DD 11 02 5D E3 00 11 00 5D E3 00 3F 40 FD 3F 34 DB 3F 40 FD 3F 34 DB 3F 40 FD 3F 34 DB 3F 40 FD 3F 34 DB 3F 4A E1 3F 30 A0 00 00 01 00 00 01 22 C0 AA 02 AA 02 00
					39 01 00 00 00 00 24 EA D1 02 3C 00 04 08 80 01 72 01 72 D1 02 3C 00 07 08 80 01 AC 01 AC 00 00 00 00 01 72 01 AC 00 0C 00 00 40
					// Sleep Out
					05 00 00 00 78 00 01 11
					// Display On
					05 00 00 00 00 00 01 29
					// Esd on
					39 00 00 40 00 00 06 F0 55 AA 52 08 00
					15 00 00 40 00 00 02 6F 05
					15 00 00 00 00 00 02 BE 08
				];
				qcom,mdss-dsi-on-command-state = "dsi_lp_mode";

				qcom,mdss-dsi-esync-post-on-commands = [
					39 01 00 40 00 00 06 F0 55 AA 52 08 03
					39 01 00 40 00 00 02 6F 06
					// 00 -> MIPI Hsync  01 -> Ext Hsync
					39 01 00 00 00 00 02 BA 01
				];
				qcom,mdss-dsi-esync-post-on-commands-state = "dsi_hs_mode";

				qcom,mdss-dsi-qsync-freq-step-sequence-interval =
					<0 120000 1>, <0 60000 1>, <1 120000 1>, <1 60000 1>;
				qcom,mdss-dsi-qsync-freq-step-sequence  =
					<30000 1>,
					<30000 1>,
					<30000 1>,
					<30000 1>;

				qcom,mdss-dsi-qsync-freq-pattren-needs-selfrefresh =
					<1 1 1 1>;

				qcom,mdss-dsi-freq-step-pattern1-command = [
					// Non Cmd Setting
					15 01 00 00 00 00 02 6F 00
				];
				qcom,mdss-dsi-freq-step-pattern1-command-state = "dsi_lp_mode";

				qcom,mdss-dsi-freq-step-pattern2-command = [
					// Non Cmd Setting
					15 01 00 00 00 00 02 6F 00
				];
				qcom,mdss-dsi-freq-step-pattern2-command-state = "dsi_lp_mode";

				qcom,mdss-dsi-freq-step-pattern3-command = [
					// Non Cmd Setting
					15 01 00 00 00 00 02 6F 00
				];
				qcom,mdss-dsi-freq-step-pattern3-command-state = "dsi_lp_mode";

				qcom,mdss-dsi-freq-step-pattern4-command = [
					// Non Cmd Setting
					15 01 00 00 00 00 02 6F 00
				];
				qcom,mdss-dsi-freq-step-pattern4-command-state = "dsi_lp_mode";

				qcom,mdss-dsi-sticky_still_en-command = [
					39 01 00 00 00 00 11 A9 10 18 00 00 01 20 D1 6E 6F 3F F0 20 BE 02 02 60
				];
				qcom,mdss-dsi-sticky_still_en-command-state = "dsi_hs_mode";

				qcom,mdss-dsi-sticky_still_disable-command = [
					39 01 00 00 00 00 11 A9 10 18 00 00 00 20 D1 6E 6F FF FF 20 BE 02 02 47
				];
				qcom,mdss-dsi-sticky_still_disable-command-state = "dsi_hs_mode";

				qcom,mdss-dsi-em-pulse-switch-command = [
					// VHM setting, PWM write common first, then write 6D
					// pwm SWITCH add
					// FFD_PWM
					39 00 00 40 00 00 06 F0 55 AA 52 08 08
					39 00 00 40 00 00 0F E1 0E 1C 2B 39 39 39 39 39 39 22 1B 17 1A 5C
					15 00 00 40 00 00 02 6F 0E
					39 00 00 40 00 00 0F E1 08 0F 16 1F 1F 1F 1F 1F 19 26 28 2A 2C 2D
					15 00 00 40 00 00 02 6F 1C
					39 00 00 40 00 00 0F E1 04 08 0B 0B 0B 0B 0B 0B 0B 0E 16 1C 1C 25
					15 00 00 40 00 00 02 6F 2A
					39 00 00 40 00 00 0F E1 04 08 0D 0B 0B 0E 0E 0D 0B 12 16 1A 1C 25
					15 00 00 40 00 00 02 6F 38
					39 00 00 40 00 00 0F E1 01 03 05 0B 06 07 08 08 0F 15 17 1D 1C 26
					39 00 00 40 00 00 0F E2 0B 16 21 2C 2C 2C 2C 2C 2C 27 1E 18 1D 37
					15 00 00 40 00 00 02 6F 0E
					39 00 00 40 00 00 0F E2 09 12 1B 24 24 24 24 24 1A 20 23 26 29 2B
					15 00 00 40 00 00 02 6F 1C
					39 00 00 40 00 00 0F E2 00 01 03 08 0A 0B 0F 12 0E 0D 11 12 20 29
					15 00 00 40 00 00 02 6F 2A
					39 00 00 40 00 00 0F E2 03 07 0A 0C 0C 0C 0C 0B 09 0E 12 16 21 2B
					15 00 00 40 00 00 02 6F 38
					39 00 00 40 00 00 0F E2 02 05 08 08 08 08 09 08 09 0E 12 18 21 2C
					39 00 00 40 00 00 0F E3 00 00 00 00 00 00 00 00 00 00 00 00 00 00
					15 00 00 40 00 00 02 6F 0E
					39 00 00 40 00 00 0F E3 00 00 00 00 00 00 00 00 00 00 00 00 00 00
					15 00 00 40 00 00 02 6F 1C
					39 00 00 40 00 00 0F E3 00 00 00 00 00 00 00 08 00 00 00 00 00 00
					15 00 00 40 00 00 02 6F 2A
					39 00 00 40 00 00 0F E3 00 00 00 00 05 05 05 05 05 04 00 00 00 00
					15 00 00 40 00 00 02 6F 38
					39 00 00 40 00 00 0F E3 00 00 00 01 02 06 08 08 07 0C 12 16 1A 22
					// LFCC_PWM_LUT
					15 00 00 40 00 00 02 68 10
					// LFCC_COM
					39 00 00 40 00 00 1A A9 10 2F 00 02 30 05 30 29 BD 00 00 05 10 A2 00 08 05 00 00 01 29 BD 00 00 04
					// pwm SWITCH
					39 01 00 40 00 00 06 F0 55 AA 52 08 00
					15 01 00 40 00 00 02 6F B8
					39 01 00 40 00 00 09 BA 22 22 22 22 22 22 22 21
					15 01 00 40 00 00 02 6F C0
					39 01 00 40 00 00 09 BA 22 22 22 22 22 22 22 21
					15 01 00 40 00 00 02 6F 5A
					39 01 00 40 00 00 09 D1 22 22 22 22 22 22 22 21
					15 01 00 40 00 00 02 6F 31
					15 01 00 40 00 00 02 C0 02
					39 01 00 40 00 00 03 5A 00 00
					// PWM VrefN1/N3 tracking ELVSS
					39 01 00 40 00 00 06 F0 55 AA 52 08 01
					15 01 00 40 00 00 02 6F 19
					39 01 00 40 00 00 06 BA 02 02 02 02 02
					15 01 00 40 00 00 02 6F 3B
					39 01 00 40 00 00 06 BA 0B 0B 0B 0B 0B
					// 6d=87
					15 01 00 40 00 00 02 6F 2D
					39 01 00 40 00 00 08 44 00 1A 00 1A 1A 0A F8
					15 01 00 40 00 00 02 6F 3B
					39 01 00 40 00 00 08 44 00 1A 00 1A 1A 0A F8
					15 01 00 40 00 00 02 6F 2B
					39 01 00 40 00 00 03 44 03 A8
					15 01 00 40 00 00 02 6F 6B
					15 01 00 40 00 00 02 44 01
					39 01 00 40 00 00 03 44 0A 60
					39 01 00 40 00 00 06 F0 55 AA 52 08 00
					15 01 00 40 00 00 02 6F 0E
					15 01 00 40 00 00 02 C0 00
					15 01 00 40 00 00 02 6F DE
					15 01 00 40 00 00 02 BA 00
					15 01 00 40 00 00 02 6F 04
					15 01 00 40 00 00 02 35 00
					15 01 00 40 00 00 02 6F 14
					15 01 00 40 00 00 02 35 6A
					15 01 00 40 00 00 02 6D 87
					// Temp value
					39 01 00 00 00 00 03 81 03 9B
				];
				qcom,mdss-dsi-em-pulse-switch-command-state = "dsi_hs_mode";

				mi,mdss-dsi-em-pulse-supplement-switch-command = [
					// VHM setting, PWM write common first, then write 6D
					// pwm SWITCH add
					// FFD_PWM
					39 00 00 40 00 00 06 F0 55 AA 52 08 08
					39 00 00 40 00 00 0F E1 0E 1C 2B 39 39 39 39 39 39 22 1B 17 1A 5C
					15 00 00 40 00 00 02 6F 0E
					39 00 00 40 00 00 0F E1 08 0F 16 1F 1F 1F 1F 1F 19 26 28 2A 2C 2D
					15 00 00 40 00 00 02 6F 1C
					39 00 00 40 00 00 0F E1 04 08 0B 0B 0B 0B 0B 0B 0B 0E 16 1C 1C 25
					15 00 00 40 00 00 02 6F 2A
					39 00 00 40 00 00 0F E1 04 08 0D 0B 0B 0E 0E 0D 0B 12 16 1A 1C 25
					15 00 00 40 00 00 02 6F 38
					39 00 00 40 00 00 0F E1 01 03 05 0B 06 07 08 08 0F 15 17 1D 1C 26
					39 00 00 40 00 00 0F E2 0B 16 21 2C 2C 2C 2C 2C 2C 27 1E 18 1D 37
					15 00 00 40 00 00 02 6F 0E
					39 00 00 40 00 00 0F E2 09 12 1B 24 24 24 24 24 1A 20 23 26 29 2B
					15 00 00 40 00 00 02 6F 1C
					39 00 00 40 00 00 0F E2 00 01 03 08 0A 0B 0F 12 0E 0D 11 12 20 29
					15 00 00 40 00 00 02 6F 2A
					39 00 00 40 00 00 0F E2 03 07 0A 0C 0C 0C 0C 0B 09 0E 12 16 21 2B
					15 00 00 40 00 00 02 6F 38
					39 00 00 40 00 00 0F E2 02 05 08 08 08 08 09 08 09 0E 12 18 21 2C
					39 00 00 40 00 00 0F E3 00 00 00 00 00 00 00 00 00 00 00 00 00 00
					15 00 00 40 00 00 02 6F 0E
					39 00 00 40 00 00 0F E3 00 00 00 00 00 00 00 00 00 00 00 00 00 00
					15 00 00 40 00 00 02 6F 1C
					39 00 00 40 00 00 0F E3 00 00 00 00 00 00 00 08 00 00 00 00 00 00
					15 00 00 40 00 00 02 6F 2A
					39 00 00 40 00 00 0F E3 00 00 00 00 05 05 05 05 05 04 00 00 00 00
					15 00 00 40 00 00 02 6F 38
					39 00 00 40 00 00 0F E3 00 00 00 01 02 06 08 08 07 0C 12 16 1A 22
					// LFCC_PWM_LUT
					15 00 00 40 00 00 02 68 10
					// LFCC_COM
					39 00 00 40 00 00 1A A9 10 2F 00 02 30 05 30 29 BD 00 00 05 10 A2 00 08 05 00 00 01 29 BD 00 00 04
					// pwm SWITCH
					39 01 00 40 00 00 06 F0 55 AA 52 08 00
					15 01 00 40 00 00 02 6F B8
					39 01 00 40 00 00 09 BA 22 22 22 22 22 22 22 21
					15 01 00 40 00 00 02 6F C0
					39 01 00 40 00 00 09 BA 22 22 22 22 22 22 22 21
					15 01 00 40 00 00 02 6F 5A
					39 01 00 40 00 00 09 D1 22 22 22 22 22 22 22 21
					15 01 00 40 00 00 02 6F 31
					15 01 00 40 00 00 02 C0 02
					39 01 00 40 00 00 03 5A 00 00
					// PWM VrefN1/N3 tracking ELVSS
					39 01 00 40 00 00 06 F0 55 AA 52 08 01
					15 01 00 40 00 00 02 6F 19
					39 01 00 40 00 00 06 BA 02 02 02 02 02
					15 01 00 40 00 00 02 6F 3B
					39 01 00 40 00 00 06 BA 0B 0B 0B 0B 0B
					// 6d=87
					15 01 00 40 00 00 02 6F 2D
					39 01 00 40 00 00 08 44 00 1A 00 1A 1A 0A F8
					15 01 00 40 00 00 02 6F 3B
					39 01 00 40 00 00 08 44 00 1A 00 1A 1A 0A F8
					15 01 00 40 00 00 02 6F 2B
					39 01 00 40 00 00 03 44 03 A8
					15 01 00 40 00 00 02 6F 6B
					15 01 00 40 00 00 02 44 01
					39 01 00 40 00 00 03 44 0A 60
					39 01 00 40 00 00 06 F0 55 AA 52 08 00
					15 01 00 40 00 00 02 6F 0E
					15 01 00 40 00 00 02 C0 00
					15 01 00 40 00 00 02 6F DE
					15 01 00 40 00 00 02 BA 00
					15 01 00 40 00 00 02 6F 04
					15 01 00 40 00 00 02 35 00
					15 01 00 40 00 00 02 6F 14
					15 01 00 40 00 00 02 35 6A
					15 01 00 40 00 00 02 6D 87
					// Temp value
					39 01 00 00 00 00 03 81 03 9B
				];
				mi,mdss-dsi-em-pulse-supplement-switch-command-state = "dsi_hs_mode";
				mi,mdss-dsi-em-pulse-supplement-switch-command-update = <0x81 64 2>;

				mi,mdss-dsi-demura-over-threshold-command = [
					15 01 00 00 00 00 02 6F 00
				];
				mi,mdss-dsi-demura-over-threshold-command-state = "dsi_hs_mode";

				mi,mdss-dsi-demura-under-threshold-command = [
					15 01 00 00 00 00 02 6F 00
				];
				mi,mdss-dsi-demura-under-threshold-command-state = "dsi_hs_mode";
			};

			timing@wqhd_normal_90hz_index_02 {
				#include "dsi-panel-p3-36-02-0b-mp-dsc-vhm-pmic-b-common.dtsi"
				cell-index = <2>;
				qcom,mdss-dsi-panel-framerate = <90>;
				qcom,mdss-dsi-v-front-porch = <1052>;

				qcom,mdss-esync-hsync-milli-pulse-width = <600>;
				qcom,mdss-esync-emsync-milli-pulse-width = <300>;
				qcom,mdss-esync-emsync-fps = <90>;
				qcom,dsi-qsync-mode-avr-step-fps = <90>;
				qcom,qsync-mode-min-refresh-rate = <30>;

				mi,mdss-dsi-current-timming-is-dc-mode = <1>;

				qcom,mdss-dsi-on-command = [
					// dbv_vld_dly_em=2
					39 00 00 40 00 00 06 F0 55 AA 52 08 00
					15 00 00 40 00 00 02 6F 70
					15 00 00 00 00 00 02 B2 02
					// EN_SSD=0
					15 00 00 40 00 00 02 6F 53
					15 00 00 00 00 00 02 D5 17
					// AP_SPR_in_Setting(RGBG)
					39 00 00 40 00 00 06 F0 55 AA 52 08 03
					15 00 00 40 00 00 02 6F 09
					39 00 00 00 00 00 07 DE 30 14 25 10 34 25
					// EM_STV_DSPOFF_MASK_OPT=1
					15 00 00 40 00 00 02 6F 10
					15 00 00 00 00 00 02 B6 15
					// External DVDD opt
					39 00 00 40 00 00 06 F0 55 AA 52 08 01
					15 00 00 40 00 00 02 6F 81
					15 00 00 00 00 00 02 C2 C2
					// AVEE_AB_HIZ
					15 00 00 40 00 00 02 6F 02
					15 00 00 00 00 00 02 C7 45
					// AP SPR IN VESA Setting
					39 00 00 40 00 00 05 2A 00 00 04 C3
					39 00 00 40 00 00 05 2B 00 00 0A 5F
					39 00 00 40 00 00 03 90 03 43
					39 00 00 40 00 00 13 91 AB F0 00 10 C1 00 01 CB 00 73 00 33 06 67 1F B0 11 40
					39 00 00 40 00 00 06 F0 55 AA 52 08 07
					39 00 00 40 00 00 06 B0 84 44 00 00 40
					15 00 00 00 00 00 02 26 00
					// TE on
					39 00 00 40 00 00 04 2F 30 05 30
					15 00 00 40 00 00 02 35 00
					15 00 00 40 00 00 02 6F 04
					15 00 00 40 00 00 02 35 00
					// TEx_sel
					15 00 00 00 00 00 02 6F 14
					39 00 00 40 00 00 04 35 6A 77 F8
					15 00 00 40 00 00 02 6F 17
					39 00 00 40 00 00 04 35 6A 77 F8
					15 00 00 40 00 00 02 6F 1A
					39 00 00 40 00 00 04 35 6A 77 F8
					15 00 00 40 00 00 02 6F 1D
					39 00 00 40 00 00 04 35 6A 77 F8
					15 00 00 40 00 00 02 6F 02
					15 00 00 40 00 00 02 35 18
					15 00 00 40 00 00 02 6F 0C
					15 00 00 40 00 00 02 35 00
					39 00 00 00 00 00 03 44 0A 60
					// dyn_multi_te_start
					15 00 00 40 00 00 02 6F 26
					39 00 00 40 00 00 03 44 00 78
					15 00 00 40 00 00 02 6F 28
					39 00 00 40 00 00 03 44 00 78
					15 00 00 40 00 00 02 6F 42
					39 00 00 40 00 00 03 44 00 78
					15 00 00 40 00 00 02 6F 64
					39 00 00 00 00 00 03 44 00 78
					// opt_level2_te_fall
					15 00 00 40 00 00 02 6F 8A
					15 00 00 00 00 00 02 44 19
					// dyn_multi_te_width
					15 00 00 40 00 00 02 6F 2A
					15 00 00 40 00 00 02 44 1A
					// still=0
					15 00 00 40 00 00 02 18 00
					// Event_Mode
					15 00 00 40 00 00 02 8C 02
					// opt_dsp_on_restart_fskip
					39 00 00 40 00 00 04 8D 00 20 00
					// opt_dis_vdo_ltpo_crc
					39 00 00 40 00 00 06 F0 55 AA 52 08 00
					15 00 00 40 00 00 02 6F DD
					15 00 00 00 00 00 02 BA 80
					// ARP_TE selects TE1F
					15 00 00 40 00 00 02 6F 35
					15 00 00 00 00 00 02 B1 10
					// SEL_ECK_CYCLE_LINE=0
					15 00 00 40 00 00 02 6F 04
					// EXTEND_VFP_LINE_ECLK_EN=0
					15 00 00 40 00 00 02 BA 00
					// tg_cmd2_opt18
					15 00 00 40 00 00 02 6F E2
					15 00 00 00 00 00 02 BA 08
					// TG_OPT2
					39 00 00 40 00 00 05 FF AA 55 A5 81
					15 00 00 40 00 00 02 6F 00
					15 00 00 40 00 00 02 FB 10
					39 00 00 40 00 00 04 8C 02 00 10
					15 00 00 40 00 00 02 6F 06
					15 00 00 40 00 00 02 6D 08
					15 00 00 00 00 00 02 53 20
					// Nor_51 00
					39 00 00 40 00 00 03 51 00 00
					// AOD_51 00
					15 00 00 40 00 00 02 6F 04
					39 00 00 00 00 00 03 51 00 00
					// 120 Hz
					15 00 00 40 00 00 02 6D 00
					// Video drop opt
					39 00 00 40 00 00 05 FF AA 55 A5 84
					15 00 00 40 00 00 02 6F 21
					15 00 00 00 00 00 02 F8 7A
					// EXT HSYNC EN
					39 00 00 40 00 00 06 F0 55 AA 52 08 03
					15 00 00 40 00 00 02 6F 06
					15 00 00 40 00 00 02 BA 00
					15 00 00 40 00 00 02 C6 87
					15 00 00 40 00 00 02 6F 2A
					15 00 00 40 00 00 02 C6 40
					39 00 00 00 00 00 06 F0 55 AA 52 08 05
					// EN AUTO VBPREM
					15 00 00 40 00 00 02 B0 9F
					// VBP EXT Setting
					39 00 00 40 00 00 05 3B 00 24 00 74
					15 00 00 40 00 00 02 6F 04
					39 00 00 40 00 00 05 3B 00 24 04 1C
					15 00 00 40 00 00 02 6F 08
					39 00 00 40 00 00 05 3B 00 24 00 74
					15 00 00 40 00 00 02 6F 10
					39 00 00 00 00 00 05 3B 00 24 00 74
					// Set DSI Mode
					15 00 00 40 00 00 02 71 01
					// Esd detection
					39 00 00 40 00 00 06 F0 55 AA 52 08 00
					15 00 00 40 00 00 02 6F 01
					15 00 00 00 00 00 02 BE 45
					// LVD on
					39 00 00 40 00 00 06 F0 55 AA 52 08 01
					15 00 00 40 00 00 02 6F 03
					15 00 00 00 00 00 02 C7 47
					// Small Pulse
					39 00 00 40 00 00 06 F0 55 AA 52 08 03
					15 00 00 40 00 00 02 6F 2A
					39 00 00 40 00 00 03 C6 40 20
					15 00 00 40 00 00 02 6F 33
					39 00 00 00 00 00 0D C6 00 20 00 20 00 20 00 20 00 20 00 20
					// Esd off
					39 00 00 40 00 00 06 F0 55 AA 52 08 00
					15 00 00 40 00 00 02 6F 05
					15 00 00 00 00 00 02 BE 00
					// VHM setting,DC first writes 6D, then writes common
					// 5.2.2.11 6d=0a
					15 01 00 40 00 00 02 6F 2D
					39 01 00 40 00 00 08 44 00 1A 00 1A 1A 0E A0
					15 01 00 40 00 00 02 6F 3B
					39 01 00 40 00 00 08 44 00 1A 00 1A 1A 0E A0
					15 01 00 40 00 00 02 6F 2B
					39 01 00 40 00 00 03 44 0E A0
					15 01 00 40 00 00 02 6F 6B
					15 01 00 40 00 00 02 44 01
					39 01 00 40 00 00 03 44 0D F0
					39 01 00 40 00 00 06 F0 55 AA 52 08 00
					15 01 00 40 00 00 02 6F 0E
					15 01 00 40 00 00 02 C0 01
					15 01 00 40 00 00 02 6F DE
					15 01 00 40 00 00 02 BA 00
					15 01 00 40 00 00 02 6F 04
					15 01 00 40 00 00 02 35 00
					15 01 00 40 00 00 02 6F 14
					15 01 00 40 00 00 02 35 6A
					15 01 00 40 00 00 02 6D 0A
					// DC switch add
					// FFD_DC
					39 00 00 40 00 00 06 F0 55 AA 52 08 08
					39 00 00 40 00 00 0F E1 0E 1C 16 16 16 16 19 19 30 22 1B 17 1A 5C
					15 00 00 40 00 00 02 6F 0E
					39 00 00 40 00 00 0F E1 08 0F 10 14 14 14 14 14 14 26 28 2A 2C 2D
					15 00 00 40 00 00 02 6F 1C
					39 00 00 40 00 00 0F E1 04 08 08 08 08 08 08 09 09 0E 16 1C 1C 25
					15 00 00 40 00 00 02 6F 2A
					39 00 00 40 00 00 0F E1 04 08 08 08 08 09 09 09 09 12 16 1A 1C 25
					15 00 00 40 00 00 02 6F 38
					39 00 00 40 00 00 0F E1 01 03 04 04 04 04 04 08 0F 15 17 1D 1C 26
					39 00 00 40 00 00 0F E2 0B 16 18 18 18 18 1A 1A 1A 27 1A 18 1D 37
					15 00 00 40 00 00 02 6F 0E
					39 00 00 40 00 00 0F E2 09 12 16 16 16 16 16 16 1A 20 23 26 29 2B
					15 00 00 40 00 00 02 6F 1C
					39 00 00 40 00 00 0F E2 00 01 0A 0C 0C 0C 0C 12 0E 0D 11 12 20 29
					15 00 00 40 00 00 02 6F 2A
					39 00 00 40 00 00 0F E2 03 07 0A 0C 0C 0C 0C 0C 09 0E 12 16 21 2B
					15 00 00 40 00 00 02 6F 38
					39 00 00 40 00 00 0F E2 02 04 05 05 05 05 05 08 09 0E 12 18 21 2C
					39 00 00 40 00 00 0F E3 00 00 01 01 01 01 00 00 00 00 00 00 00 00
					15 00 00 40 00 00 02 6F 0E
					39 00 00 40 00 00 0F E3 00 01 01 01 01 01 01 01 01 02 02 10 00 00
					15 00 00 40 00 00 02 6F 1C
					39 00 00 40 00 00 0F E3 00 01 01 01 01 01 01 08 00 00 00 00 00 00
					15 00 00 40 00 00 02 6F 2A
					39 00 00 40 00 00 0F E3 00 00 00 05 05 05 05 05 05 04 00 00 00 00
					15 00 00 40 00 00 02 6F 38
					39 00 00 40 00 00 0F E3 00 00 01 01 02 07 08 08 07 0C 12 16 1A 22
					// LFCC_DC_LUT
					15 00 00 40 00 00 02 68 00
					// LFCC_COM
					39 00 00 40 00 00 1A A9 10 2F 00 02 30 05 30 29 BD 00 00 05 10 A2 00 08 05 00 00 01 29 BD 00 00 04
					// DC switch
					39 01 00 40 00 00 06 F0 55 AA 52 08 00
					15 01 00 40 00 00 02 6F B8
					39 01 00 40 00 00 09 BA 10 10 00 00 00 01 20 21
					15 01 00 40 00 00 02 6F C0
					39 01 00 40 00 00 09 BA 10 10 00 00 00 01 20 21
					15 01 00 40 00 00 02 6F 5A
					39 01 00 40 00 00 09 D1 10 10 00 00 00 01 20 21
					15 01 00 40 00 00 02 6F 31
					15 01 00 40 00 00 02 C0 00
					39 01 00 40 00 00 03 5A 00 00
					// DC VrefN1/N3 tracking ELVSS
					39 01 00 40 00 00 06 F0 55 AA 52 08 01
					15 01 00 40 00 00 02 6F 19
					39 01 00 40 00 00 06 BA 03 03 03 03 03
					15 01 00 40 00 00 02 6F 3B
					39 01 00 40 00 00 06 BA 0C 0C 0C 0C 0C
					// video trim
					39 01 00 40 00 00 06 F0 55 AA 52 08 01
					39 01 00 40 00 00 37 C3 DD 11 02 5D E3 00 11 00 5D E3 00 3F 40 FD 3F 34 DB 3F 40 FD 3F 34 DB 3F 40 FD 3F 34 DB 3F 40 FD 3F 34 DB 3F 4A E1 3F 30 A0 00 00 01 00 00 01 22 C0 AA 02 AA 02 00
					39 01 00 00 00 00 24 EA D1 02 3C 00 04 08 80 01 72 01 72 D1 02 3C 00 07 08 80 01 AC 01 AC 00 00 00 00 01 72 01 AC 00 0C 00 00 40
					// Sleep Out
					05 00 00 00 78 00 01 11
					// Display On
					05 00 00 00 00 00 01 29
					// Esd on
					39 00 00 40 00 00 06 F0 55 AA 52 08 00
					15 00 00 40 00 00 02 6F 05
					15 00 00 00 00 00 02 BE 08
				];
				qcom,mdss-dsi-on-command-state = "dsi_lp_mode";

				qcom,mdss-dsi-esync-post-on-commands = [
					39 01 00 40 00 00 06 F0 55 AA 52 08 03
					39 01 00 40 00 00 02 6F 06
					// 00 -> MIPI Hsync  01 -> Ext Hsync
					39 01 00 00 00 00 02 BA 01
				];
				qcom,mdss-dsi-esync-post-on-commands-state = "dsi_hs_mode";

				qcom,mdss-dsi-qsync-freq-step-sequence-interval =
					<0 120000 1>, <0 60000 1>, <1 120000 1>, <1 60000 1>;
				qcom,mdss-dsi-qsync-freq-step-sequence  =
					<30000 1>,
					<30000 1>,
					<30000 1>,
					<30000 1>;

				qcom,mdss-dsi-qsync-freq-pattren-needs-selfrefresh =
					<1 1 1 1>;

				qcom,mdss-dsi-freq-step-pattern1-command = [
					// Non Cmd Setting
					15 01 00 00 00 00 02 6F 00
				];
				qcom,mdss-dsi-freq-step-pattern1-command-state = "dsi_lp_mode";

				qcom,mdss-dsi-freq-step-pattern2-command = [
					// Non Cmd Setting
					15 01 00 00 00 00 02 6F 00
				];
				qcom,mdss-dsi-freq-step-pattern2-command-state = "dsi_lp_mode";

				qcom,mdss-dsi-freq-step-pattern3-command = [
					// Non Cmd Setting
					15 01 00 00 00 00 02 6F 00
				];
				qcom,mdss-dsi-freq-step-pattern3-command-state = "dsi_lp_mode";

				qcom,mdss-dsi-freq-step-pattern4-command = [
					// Non Cmd Setting
					15 01 00 00 00 00 02 6F 00
				];
				qcom,mdss-dsi-freq-step-pattern4-command-state = "dsi_lp_mode";

				qcom,mdss-dsi-sticky_still_en-command = [
					39 01 00 00 00 00 11 A9 10 18 00 00 01 20 D1 6E 6F 3F F0 20 BE 02 02 60
				];
				qcom,mdss-dsi-sticky_still_en-command-state = "dsi_hs_mode";

				qcom,mdss-dsi-sticky_still_disable-command = [
					39 01 00 00 00 00 11 A9 10 18 00 00 00 20 D1 6E 6F FF FF 20 BE 02 02 47
				];
				qcom,mdss-dsi-sticky_still_disable-command-state = "dsi_hs_mode";

				qcom,mdss-dsi-em-pulse-switch-command = [
					// VHM setting,DC first writes 6D, then writes common
					// 5.2.2.11 6d=0a
					15 01 00 40 00 00 02 6F 2D
					39 01 00 40 00 00 08 44 00 1A 00 1A 1A 0E A0
					15 01 00 40 00 00 02 6F 3B
					39 01 00 40 00 00 08 44 00 1A 00 1A 1A 0E A0
					15 01 00 40 00 00 02 6F 2B
					39 01 00 40 00 00 03 44 0E A0
					15 01 00 40 00 00 02 6F 6B
					15 01 00 40 00 00 02 44 01
					39 01 00 40 00 00 03 44 0D F0
					39 01 00 40 00 00 06 F0 55 AA 52 08 00
					15 01 00 40 00 00 02 6F 0E
					15 01 00 40 00 00 02 C0 01
					15 01 00 40 00 00 02 6F DE
					15 01 00 40 00 00 02 BA 00
					15 01 00 40 00 00 02 6F 04
					15 01 00 40 00 00 02 35 00
					15 01 00 40 00 00 02 6F 14
					15 01 00 40 00 00 02 35 6A
					15 01 00 00 00 00 02 6D 0A
				];
				qcom,mdss-dsi-em-pulse-switch-command-state = "dsi_hs_mode";

				mi,mdss-dsi-em-pulse-supplement-switch-command = [
					// VHM setting,DC first writes 6D, then writes common
					// 5.2.2.11 6d=0a
					15 01 00 40 00 00 02 6F 2D
					39 01 00 40 00 00 08 44 00 1A 00 1A 1A 0E A0
					15 01 00 40 00 00 02 6F 3B
					39 01 00 40 00 00 08 44 00 1A 00 1A 1A 0E A0
					15 01 00 40 00 00 02 6F 2B
					39 01 00 40 00 00 03 44 0E A0
					15 01 00 40 00 00 02 6F 6B
					15 01 00 40 00 00 02 44 01
					39 01 00 40 00 00 03 44 0D F0
					39 01 00 40 00 00 06 F0 55 AA 52 08 00
					15 01 00 40 00 00 02 6F 0E
					15 01 00 40 00 00 02 C0 01
					15 01 00 40 00 00 02 6F DE
					15 01 00 40 00 00 02 BA 00
					15 01 00 40 00 00 02 6F 04
					15 01 00 40 00 00 02 35 00
					15 01 00 40 00 00 02 6F 14
					15 01 00 40 00 00 02 35 6A
					15 01 00 40 00 00 02 6D 0A
					// DC switch add
					// FFD_DC
					39 00 00 40 00 00 06 F0 55 AA 52 08 08
					39 00 00 40 00 00 0F E1 0E 1C 16 16 16 16 19 19 30 22 1B 17 1A 5C
					15 00 00 40 00 00 02 6F 0E
					39 00 00 40 00 00 0F E1 08 0F 10 14 14 14 14 14 14 26 28 2A 2C 2D
					15 00 00 40 00 00 02 6F 1C
					39 00 00 40 00 00 0F E1 04 08 08 08 08 08 08 09 09 0E 16 1C 1C 25
					15 00 00 40 00 00 02 6F 2A
					39 00 00 40 00 00 0F E1 04 08 08 08 08 09 09 09 09 12 16 1A 1C 25
					15 00 00 40 00 00 02 6F 38
					39 00 00 40 00 00 0F E1 01 03 04 04 04 04 04 08 0F 15 17 1D 1C 26
					39 00 00 40 00 00 0F E2 0B 16 18 18 18 18 1A 1A 1A 27 1A 18 1D 37
					15 00 00 40 00 00 02 6F 0E
					39 00 00 40 00 00 0F E2 09 12 16 16 16 16 16 16 1A 20 23 26 29 2B
					15 00 00 40 00 00 02 6F 1C
					39 00 00 40 00 00 0F E2 00 01 0A 0C 0C 0C 0C 12 0E 0D 11 12 20 29
					15 00 00 40 00 00 02 6F 2A
					39 00 00 40 00 00 0F E2 03 07 0A 0C 0C 0C 0C 0C 09 0E 12 16 21 2B
					15 00 00 40 00 00 02 6F 38
					39 00 00 40 00 00 0F E2 02 04 05 05 05 05 05 08 09 0E 12 18 21 2C
					39 00 00 40 00 00 0F E3 00 00 01 01 01 01 00 00 00 00 00 00 00 00
					15 00 00 40 00 00 02 6F 0E
					39 00 00 40 00 00 0F E3 00 01 01 01 01 01 01 01 01 02 02 10 00 00
					15 00 00 40 00 00 02 6F 1C
					39 00 00 40 00 00 0F E3 00 01 01 01 01 01 01 08 00 00 00 00 00 00
					15 00 00 40 00 00 02 6F 2A
					39 00 00 40 00 00 0F E3 00 00 00 05 05 05 05 05 05 04 00 00 00 00
					15 00 00 40 00 00 02 6F 38
					39 00 00 40 00 00 0F E3 00 00 01 01 02 07 08 08 07 0C 12 16 1A 22
					// LFCC_DC_LUT
					15 00 00 40 00 00 02 68 00
					// LFCC_COM
					39 00 00 40 00 00 1A A9 10 2F 00 02 30 05 30 29 BD 00 00 05 10 A2 00 08 05 00 00 01 29 BD 00 00 04
					// DC switch
					39 01 00 40 00 00 06 F0 55 AA 52 08 00
					15 01 00 40 00 00 02 6F B8
					39 01 00 40 00 00 09 BA 10 10 00 00 00 01 20 21
					15 01 00 40 00 00 02 6F C0
					39 01 00 40 00 00 09 BA 10 10 00 00 00 01 20 21
					15 01 00 40 00 00 02 6F 5A
					39 01 00 40 00 00 09 D1 10 10 00 00 00 01 20 21
					15 01 00 40 00 00 02 6F 31
					15 01 00 40 00 00 02 C0 00
					39 01 00 40 00 00 03 5A 00 00
					// DC VrefN1/N3 tracking ELVSS
					39 01 00 40 00 00 06 F0 55 AA 52 08 01
					15 01 00 40 00 00 02 6F 19
					39 01 00 40 00 00 06 BA 03 03 03 03 03
					15 01 00 40 00 00 02 6F 3B
					39 01 00 40 00 00 06 BA 0C 0C 0C 0C 0C
					// Temp value
					39 01 00 00 00 00 03 81 03 1B
				];
				mi,mdss-dsi-em-pulse-supplement-switch-command-state = "dsi_hs_mode";
				mi,mdss-dsi-em-pulse-supplement-switch-command-update = <0x81 64 2>;

				mi,mdss-dsi-demura-over-threshold-command = [
					15 01 00 00 00 00 02 6F 00
				];
				mi,mdss-dsi-demura-over-threshold-command-state = "dsi_hs_mode";

				mi,mdss-dsi-demura-under-threshold-command = [
					15 01 00 00 00 00 02 6F 00
				];
				mi,mdss-dsi-demura-under-threshold-command-state = "dsi_hs_mode";
			};
		};
	};
};

&dsi_p3_36_02_0b_mp_dsc_vhm_pmic_b {
	qcom,panel-supply-entries = <&dsi_panel_pwr_supply_p3_b>;
	qcom,panel-post-supply-entries = <&dsi_panel_pwr_post_supply_p3_b>;
	qcom,mdss-dsi-bl-pmic-control-type = "bl_ctrl_dcs";
	qcom,mdss-dsi-bl-min-level = <7>;
	qcom,mdss-dsi-bl-max-level = <16383>;
	qcom,bl-dsc-cmd-state = "dsi_hs_mode";
	qcom,mdss-brightness-max-level = <16383>;
	qcom,mdss-brightness-init-level = <916>;
	qcom,platform-reset-gpio = <&tlmm 98 0>;
	qcom,platform-pmic-reset-gpio = <&tlmm 171 0>;

	mi,mdss-dsi-actual-bl-max-level = <16382>;
	mi,panel-id = <0x00005033 0x0036020B>;
	mi,panel-on-dimming-delay = <120>;

	/* IRQF_ONESHOT | IRQF_TRIGGER_HEIGH */
	mi,esd-err-irq-gpio = <&tlmm 97 0x2004>;
	mi,esd-err-irq-gpio-flag = <0x2004>;

	mi,mdss-dsi-fac-bl-max-level = <8191>;
	mi,mdss-fac-brightness-max-level = <8191>;
	mi,max-brightness-normal = <6142>;

	mi,mdss-dsi-panel-wp-read-command = [06 01 00 02 00 00 01 A1];
	mi,mdss-dsi-panel-wp-read-command-state = "dsi_hs_mode";
	mi,mdss-dsi-panel-wp-read-length = <3>;

	mi,mdss-dsi-panel-cell-id-read-command = [06 01 00 00 00 00 01 AC];
	mi,mdss-dsi-panel-cell-id-read-command-state = "dsi_hs_mode";
	mi,mdss-dsi-panel-cell-id-read-length = <16>;

	mi,panel-build-id-read-needed;
	mi,panel-build-id-read-length = <1>;
	mi,mdss-dsi-panel-build-id-read-command = [06 01 00 00 00 00 01 DB];
	mi,mdss-dsi-panel-build-id-read-command-state = "dsi_hs_mode";

	mi,flatmode-status-check-enabled;
	mi,mdss-dsi-panel-flatmode-status-command = [
		06 01 00 01 00 00 01 5F
	];
	mi,mdss-dsi-panel-flatmode-status-command-state = "dsi_hs_mode";
	mi,mdss-dsi-panel-flatmode-status-read-length = <1>;
	mi,mdss-dsi-panel-flatmode-on-status-value = <0x00>;

	mi,doze-hbm-dbv-level = <412>;
	mi,doze-lbm-dbv-level = <35>;

	mi,mdss-dsi-panel-dc-demura-threshold = <607>;
	mi,dc-feature-enabled;
	mi,ddic-round-corner-enabled;
	mi,is-tddi-flag;//for double click

	qcom,ulps-enabled;
	qcom,dsi-select-clocks = "pll_byte_clk0", "pll_dsi_clk0";
	qcom,mdss-dsi-clk-strength = <0x88>;

	qcom,mdss-esync;
	qcom,mdss-dsi-panel-esync-emsync-switch-enabled;

	qcom,qsync-enable;
	qcom,vrr-enable;
	qcom,video-psr-enable;

	//qcom,dsi-qsync-avr-disable-hw-trigger;
	qcom,mdss-dsi-qsync-min-refresh-rate = <30>;
	qcom,dsi-qsync-avr-step-fps = <120>;
};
